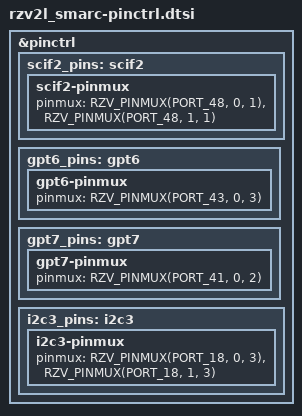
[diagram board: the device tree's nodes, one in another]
/*
 * Copyright (c) 2025 Renesas Electronics Corporation
 * SPDX-License-Identifier: Apache-2.0
 */

#include <zephyr/dt-bindings/gpio/gpio.h>
#include <zephyr/dt-bindings/pinctrl/renesas/pinctrl-rzv-common.h>

&pinctrl {
	/omit-if-no-ref/ scif2_pins: scif2 {
		scif2-pinmux {
			pinmux = <RZV_PINMUX(PORT_48, 0, 1)>, /* TXD */
				 <RZV_PINMUX(PORT_48, 1, 1)>; /* RXD */
		};
	};

	/omit-if-no-ref/ gpt6_pins: gpt6 {
		gpt6-pinmux {
			pinmux = <RZV_PINMUX(PORT_43, 0, 3)>; /* GTIOCA */
		};
	};

	/omit-if-no-ref/ gpt7_pins: gpt7 {
		gpt7-pinmux {
			pinmux = <RZV_PINMUX(PORT_41, 0, 2)>; /* GTIOCA */
		};
	};

	/omit-if-no-ref/ i2c3_pins: i2c3 {
		i2c3-pinmux {
			pinmux = <RZV_PINMUX(PORT_18, 0, 3)>, /* SDA */
				 <RZV_PINMUX(PORT_18, 1, 3)>; /* SCL */
		};
	};
};
